# STM32L4R9ZIY6P register map
File version: 1.0
Registers are 32-bit, access not given, reset 0x0 unless marked. A register's access mark holds for its fields unless they carry their own. Offsets are from the block's base; [hi:lo] are bit positions; {n}, {i} and the like mark numbered series; 'fields as' and 'values as' point back to an identical list.

## ADC1
Base 0x50040000
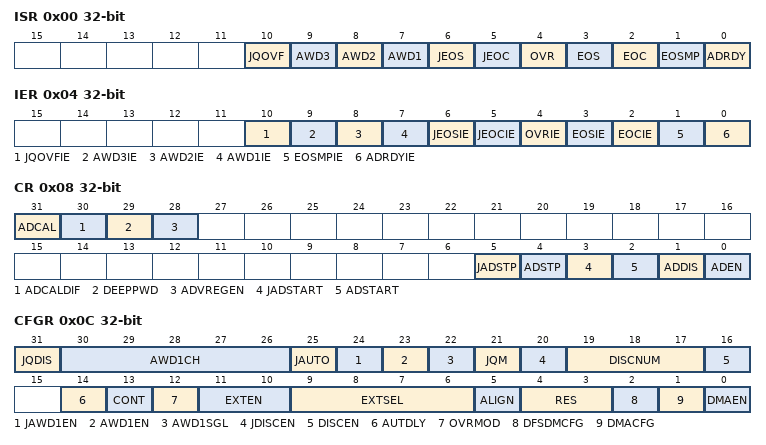
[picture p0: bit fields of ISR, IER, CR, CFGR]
0x00 ISR
  [10] JQOVF, [9] AWD3, [8] AWD2, [7] AWD1, [6] JEOS, [5] JEOC, [4] OVR, [3] EOS, [2] EOC, [1] EOSMP, [0] ADRDY
0x04 IER
  [10] JQOVFIE, [9] AWD3IE, [8] AWD2IE, [7] AWD1IE, [6] JEOSIE, [5] JEOCIE, [4] OVRIE, [3] EOSIE, [2] EOCIE, [1] EOSMPIE, [0] ADRDYIE
0x08 CR
  [31] ADCAL, [30] ADCALDIF, [29] DEEPPWD, [28] ADVREGEN, [5] JADSTP, [4] ADSTP, [3] JADSTART, [2] ADSTART, [1] ADDIS, [0] ADEN
0x0C CFGR
  [31] JQDIS, [30:26] AWD1CH, [25] JAUTO, [24] JAWD1EN, [23] AWD1EN, [22] AWD1SGL, [21] JQM, [20] JDISCEN, [19:17] DISCNUM, [16] DISCEN, [14] AUTDLY, [13] CONT, [12] OVRMOD, [11:10] EXTEN, [9:6] EXTSEL, [5] ALIGN, [4:3] RES, [2] DFSDMCFG, [1] DMACFG, [0] DMAEN
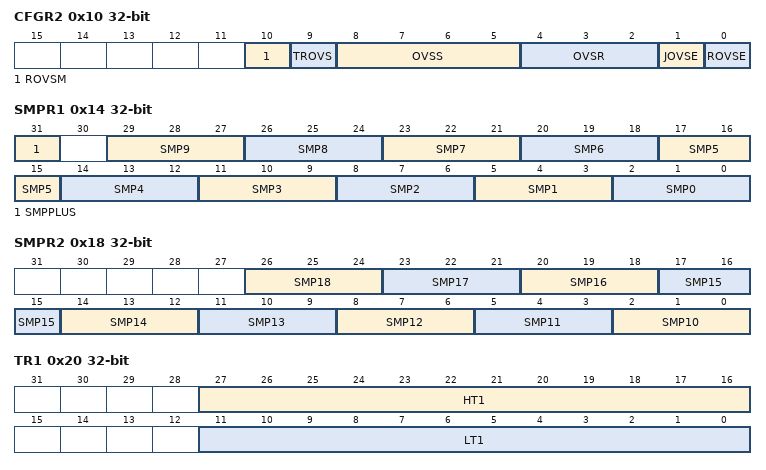
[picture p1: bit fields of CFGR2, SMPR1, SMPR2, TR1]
0x10 CFGR2
  [10] ROVSM, [9] TROVS, [8:5] OVSS, [4:2] OVSR, [1] JOVSE, [0] ROVSE
0x14 SMPR1
  [31] SMPPLUS, [3n+2:3n] SMP{n} (n=0..9)
0x18 SMPR2
  [3n-28:3n-30] SMP{n} (n=10..18)
0x20 TR1
  [27:16] HT1, [11:0] LT1
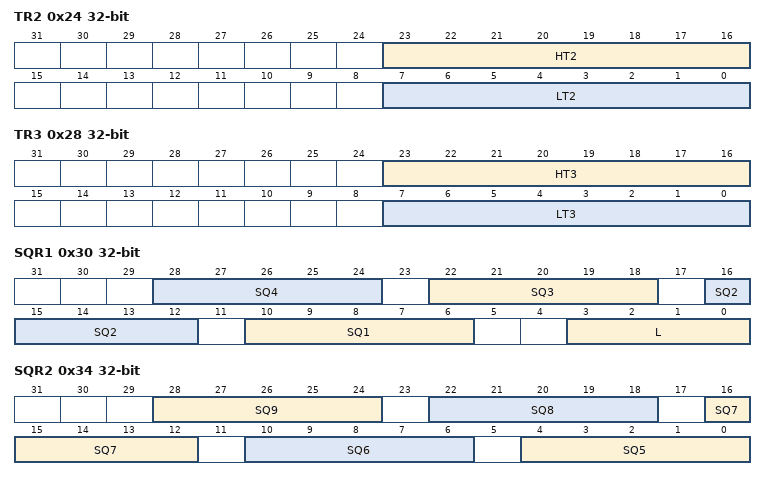
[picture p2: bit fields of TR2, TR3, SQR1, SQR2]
0x24 TR2
  [23:16] HT2, [7:0] LT2
0x28 TR3
  [23:16] HT3, [7:0] LT3
0x30 SQR1
  [6n+4:6n] SQ{n} (n=1..4), [3:0] L
0x34 SQR2
  [6n-26:6n-30] SQ{n} (n=5..9)
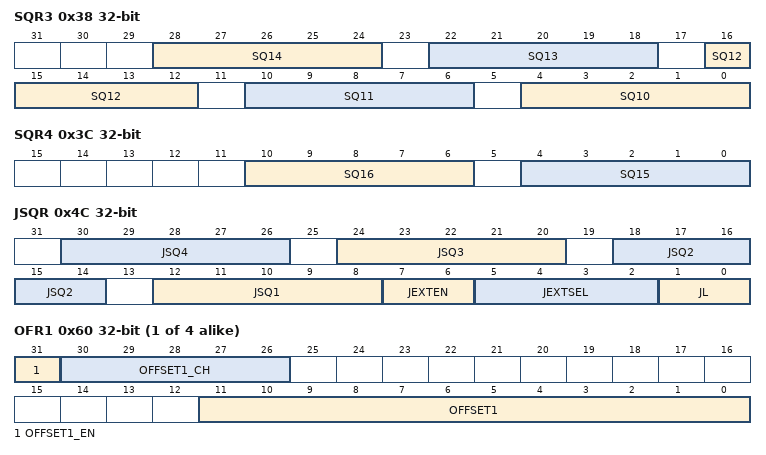
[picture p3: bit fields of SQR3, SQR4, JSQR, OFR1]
0x38 SQR3
  [6n-56:6n-60] SQ{n} (n=10..14)
0x3C SQR4
  [10:6] SQ16, [4:0] SQ15
0x40 DR
  [15:0] RDATA
0x4C JSQR
  [6n+6:6n+2] JSQ{n} (n=1..4), [7:6] JEXTEN, [5:2] JEXTSEL, [1:0] JL
{0x5C+4i} OFR{i} (i=1..4)
  [31] OFFSET{i}_EN, [30:26] OFFSET{i}_CH, [11:0] OFFSET{i}
{0x7C+4i} JDR{i} (i=1..4)
  [15:0] JDATA
0xA0 AWD2CR
  [18:0] AWD2CH
0xA4 AWD3CR
  [18:0] AWD3CH
0xB0 DIFSEL
  [18:0] DIFSEL
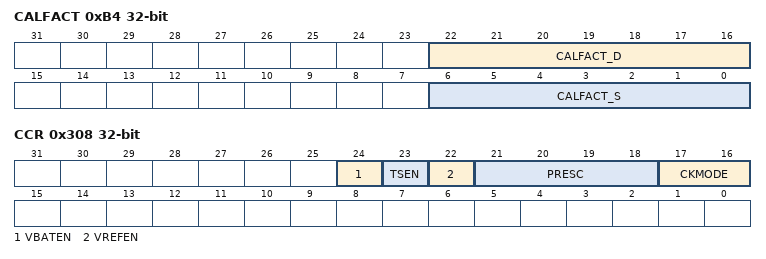
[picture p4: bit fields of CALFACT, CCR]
0xB4 CALFACT
  [22:16] CALFACT_D, [6:0] CALFACT_S
0x308 CCR
  [24] VBATEN, [23] TSEN, [22] VREFEN, [21:18] PRESC, [17:16] CKMODE

## DCMI
Base 0x50050000
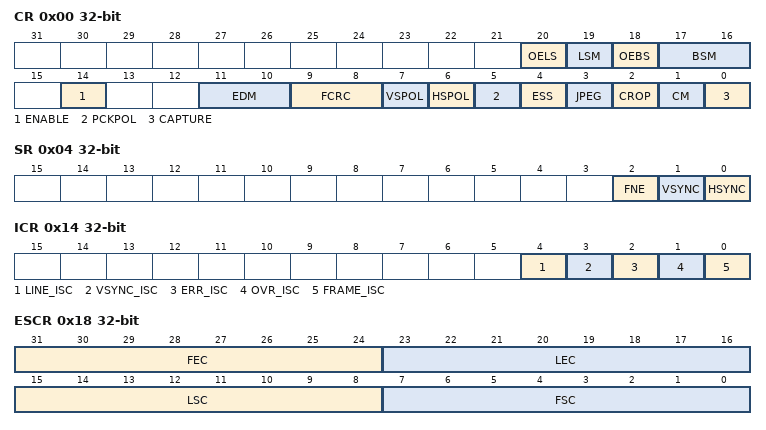
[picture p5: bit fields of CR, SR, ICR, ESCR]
0x00 CR
  [20] OELS, [19] LSM, [18] OEBS, [17:16] BSM, [14] ENABLE, [11:10] EDM, [9:8] FCRC, [7] VSPOL, [6] HSPOL, [5] PCKPOL, [4] ESS, [3] JPEG, [2] CROP, [1] CM, [0] CAPTURE
0x04 SR
  [2] FNE, [1] VSYNC, [0] HSYNC
0x08 RISR
0x0C IER
  [4] LINE_IE, [3] VSYNC_IE, [2] ERR_IE, [1] OVR_IE, [4:0] INT_IE
0x10 MISR
0x14 ICR
  [4] LINE_ISC, [3] VSYNC_ISC, [2] ERR_ISC, [1] OVR_ISC, [0] FRAME_ISC
0x18 ESCR
  [31:24] FEC, [23:16] LEC, [15:8] LSC, [7:0] FSC
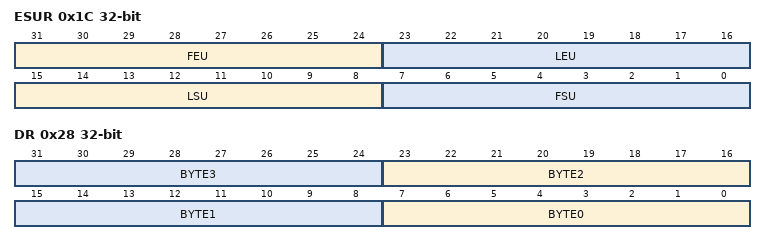
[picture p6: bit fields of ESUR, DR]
0x1C ESUR
  [31:24] FEU, [23:16] LEU, [15:8] LSU, [7:0] FSU
0x20 CWSTRTR
0x24 CWSIZER
0x28 DR
  [8n+7:8n] BYTE{n} (n=0..3)

## RNG
Base 0x50060800
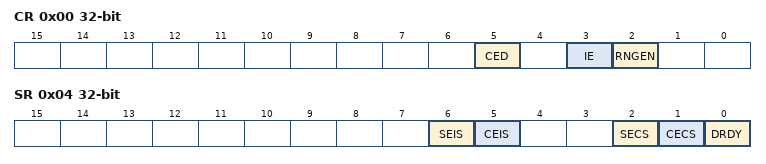
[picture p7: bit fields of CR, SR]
0x00 CR
  [5] CED, [3] IE, [2] RNGEN
0x04 SR
  [6] SEIS, [5] CEIS, [2] SECS, [1] CECS, [0] DRDY
0x08 DR

## OCTOSPIM
Base 0x50061C00
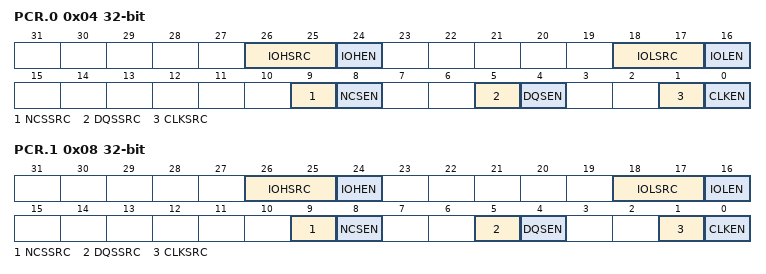
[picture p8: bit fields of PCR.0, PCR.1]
0x04 PCR.0
  [26:25] IOHSRC, [24] IOHEN, [18:17] IOLSRC, [16] IOLEN, [9] NCSSRC, [8] NCSEN, [5] DQSSRC, [4] DQSEN, [1] CLKSRC, [0] CLKEN
0x08 PCR.1
  fields as PCR.0

## SDMMC1
Base 0x50062400
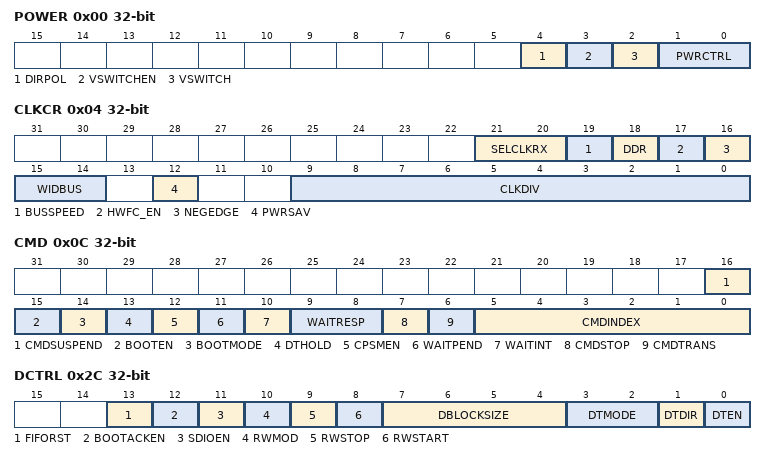
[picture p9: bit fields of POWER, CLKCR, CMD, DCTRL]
0x00 POWER
  [4] DIRPOL, [3] VSWITCHEN, [2] VSWITCH, [1:0] PWRCTRL
0x04 CLKCR
  [21:20] SELCLKRX, [19] BUSSPEED, [18] DDR, [17] HWFC_EN, [16] NEGEDGE, [15:14] WIDBUS, [12] PWRSAV, [9:0] CLKDIV
0x08 ARG
  [31:0] CMDARG
0x0C CMD
  [16] CMDSUSPEND, [15] BOOTEN, [14] BOOTMODE, [13] DTHOLD, [12] CPSMEN, [11] WAITPEND, [10] WAITINT, [9:8] WAITRESP, [7] CMDSTOP, [6] CMDTRANS, [5:0] CMDINDEX
0x10 RESPCMD
  [5:0] RESPCMD
{0x10+4i} RESP{i} (i=1..4)
  [31:0] CARDSTATUS{i}
0x24 DTIMER
  [31:0] DATATIME
0x28 DLEN
  [24:0] DATALENGTH
0x2C DCTRL
  [13] FIFORST, [12] BOOTACKEN, [11] SDIOEN, [10] RWMOD, [9] RWSTOP, [8] RWSTART, [7:4] DBLOCKSIZE, [3:2] DTMODE, [1] DTDIR, [0] DTEN
0x30 DCOUNT
  [24:0] DATACOUNT
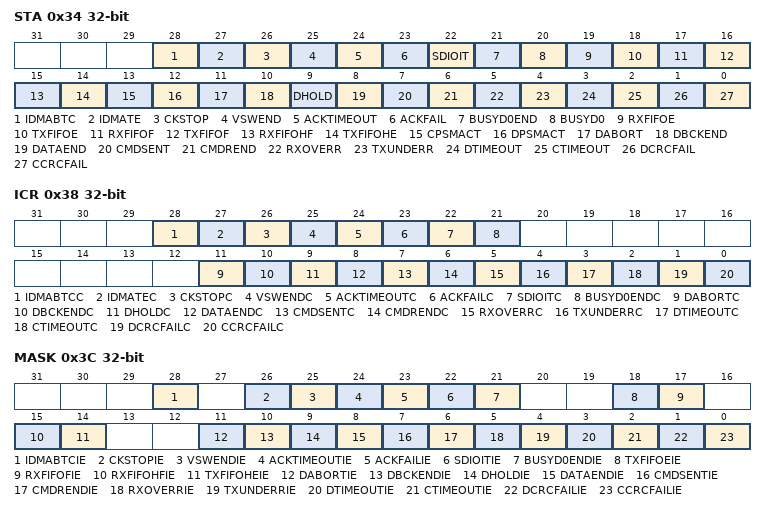
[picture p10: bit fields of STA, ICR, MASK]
0x34 STA
  [28] IDMABTC, [27] IDMATE, [26] CKSTOP, [25] VSWEND, [24] ACKTIMEOUT, [23] ACKFAIL, [22] SDIOIT, [21] BUSYD0END, [20] BUSYD0, [19] RXFIFOE, [18] TXFIFOE, [17] RXFIFOF, [16] TXFIFOF, [15] RXFIFOHF, [14] TXFIFOHE, [13] CPSMACT, [12] DPSMACT, [11] DABORT, [10] DBCKEND, [9] DHOLD, [8] DATAEND, [7] CMDSENT, [6] CMDREND, [5] RXOVERR, [4] TXUNDERR, [3] DTIMEOUT, [2] CTIMEOUT, [1] DCRCFAIL, [0] CCRCFAIL
0x38 ICR
  [28] IDMABTCC, [27] IDMATEC, [26] CKSTOPC, [25] VSWENDC, [24] ACKTIMEOUTC, [23] ACKFAILC, [22] SDIOITC, [21] BUSYD0ENDC, [11] DABORTC, [10] DBCKENDC, [9] DHOLDC, [8] DATAENDC, [7] CMDSENTC, [6] CMDRENDC, [5] RXOVERRC, [4] TXUNDERRC, [3] DTIMEOUTC, [2] CTIMEOUTC, [1] DCRCFAILC, [0] CCRCFAILC
0x3C MASK
  [28] IDMABTCIE, [26] CKSTOPIE, [25] VSWENDIE, [24] ACKTIMEOUTIE, [23] ACKFAILIE, [22] SDIOITIE, [21] BUSYD0ENDIE, [18] TXFIFOEIE, [17] RXFIFOFIE, [15] RXFIFOHFIE, [14] TXFIFOHEIE, [11] DABORTIE, [10] DBCKENDIE, [9] DHOLDIE, [8] DATAENDIE, [7] CMDSENTIE, [6] CMDRENDIE, [5] RXOVERRIE, [4] TXUNDERRIE, [3] DTIMEOUTIE, [2] CTIMEOUTIE, [1] DCRCFAILIE, [0] CCRCFAILIE
0x40 ACKTIME
0x50 IDMACTRL
0x54 IDMABSIZE
0x58 IDMABASE0
0x5C IDMABASE1
0x80 FIFO
  [31:0] FIFODATA

## FMC_Bank1_R
Base 0xA0000000
0x00 BTCR.0
0x04 BTCR.1
0x08 BTCR.2
0x0C BTCR.3
0x10 BTCR.4
0x14 BTCR.5
0x18 BTCR.6
0x1C BTCR.7

## FMC_Bank3_R
Base 0xA0000080
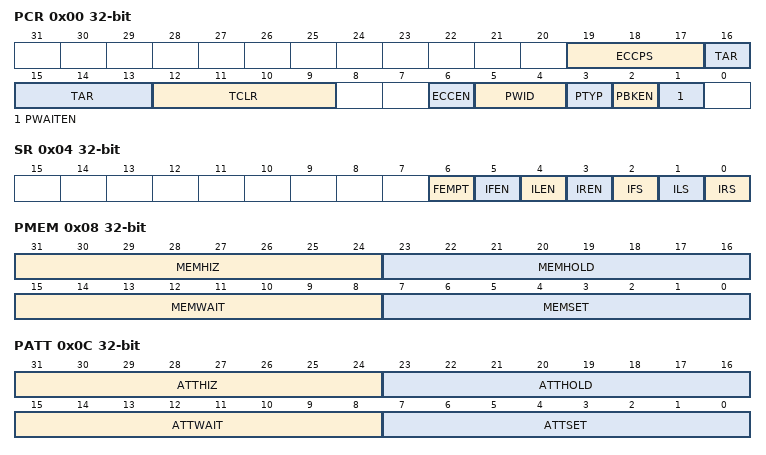
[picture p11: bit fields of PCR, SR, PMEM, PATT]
0x00 PCR
  [19:17] ECCPS, [16:13] TAR, [12:9] TCLR, [6] ECCEN, [5:4] PWID, [3] PTYP, [2] PBKEN, [1] PWAITEN
0x04 SR
  [6] FEMPT, [5] IFEN, [4] ILEN, [3] IREN, [2] IFS, [1] ILS, [0] IRS
0x08 PMEM
  [31:24] MEMHIZ, [23:16] MEMHOLD, [15:8] MEMWAIT, [7:0] MEMSET
0x0C PATT
  [31:24] ATTHIZ, [23:16] ATTHOLD, [15:8] ATTWAIT, [7:0] ATTSET
0x14 ECCR
  [31:0] ECC

## FMC_Bank1E_R
Base 0xA0000104
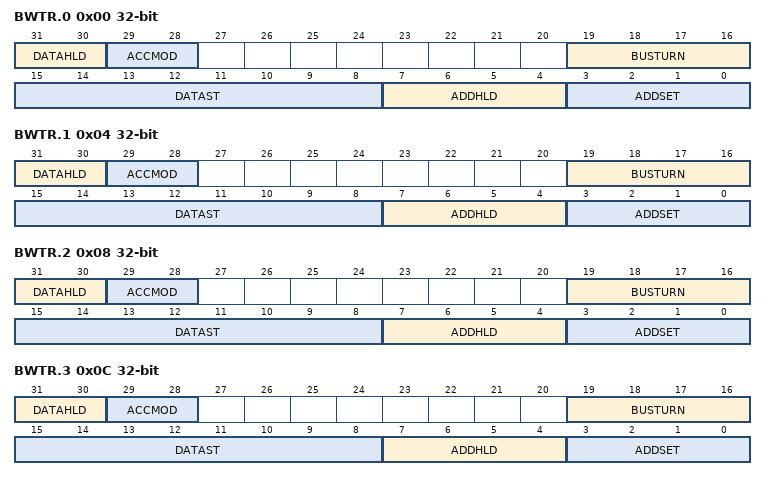
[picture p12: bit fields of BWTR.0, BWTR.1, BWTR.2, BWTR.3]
0x00 BWTR.0
  [31:30] DATAHLD, [29:28] ACCMOD, [19:16] BUSTURN, [15:8] DATAST, [7:4] ADDHLD, [3:0] ADDSET
0x04 BWTR.1
  fields as BWTR.0
0x08 BWTR.2
  fields as BWTR.0
0x0C BWTR.3
  fields as BWTR.0
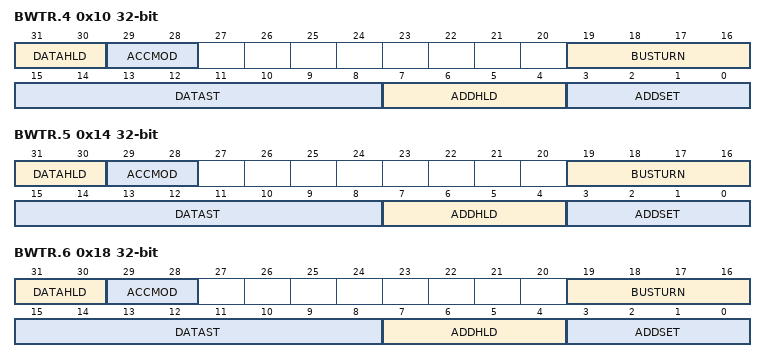
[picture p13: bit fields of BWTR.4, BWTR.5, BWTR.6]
0x10 BWTR.4
  fields as BWTR.0
0x14 BWTR.5
  fields as BWTR.0
0x18 BWTR.6
  fields as BWTR.0

## OCTOSPI1
Base 0xA0001000
Same registers: OCTOSPI2 0xA0001400
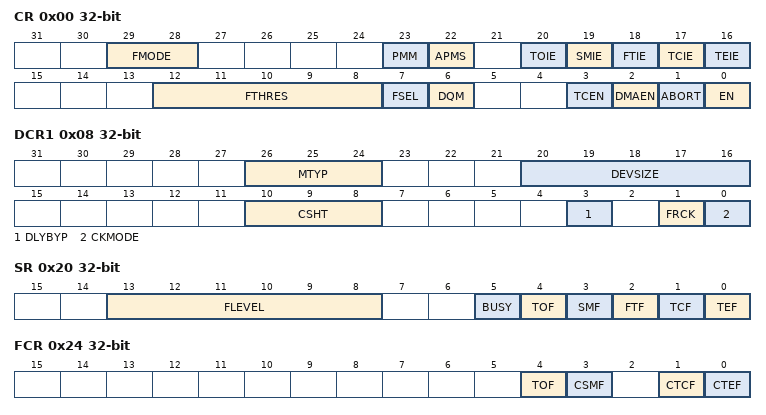
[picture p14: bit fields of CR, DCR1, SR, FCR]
0x00 CR
  [29:28] FMODE, [23] PMM, [22] APMS, [20] TOIE, [19] SMIE, [18] FTIE, [17] TCIE, [16] TEIE, [12:8] FTHRES, [7] FSEL, [6] DQM, [3] TCEN, [2] DMAEN, [1] ABORT, [0] EN
0x08 DCR1
  [26:24] MTYP, [20:16] DEVSIZE, [10:8] CSHT, [3] DLYBYP, [1] FRCK, [0] CKMODE
0x0C DCR2
  [7:0] PRESCALER
0x10 DCR3
  [20:16] CSBOUND
0x20 SR
  [13:8] FLEVEL, [5] BUSY, [4] TOF, [3] SMF, [2] FTF, [1] TCF, [0] TEF
0x24 FCR
  [4] TOF, [3] CSMF, [1] CTCF, [0] CTEF
0x40 DLR
  [31:0] DL
0x48 AR
  [31:0] ADDRESS
0x50 DR
  [31:0] DATA
0x80 PSMKR
  [31:0] MASK
0x88 PSMAR
  [31:0] MATCH
0x90 PIR
  [15:0] INTERVAL
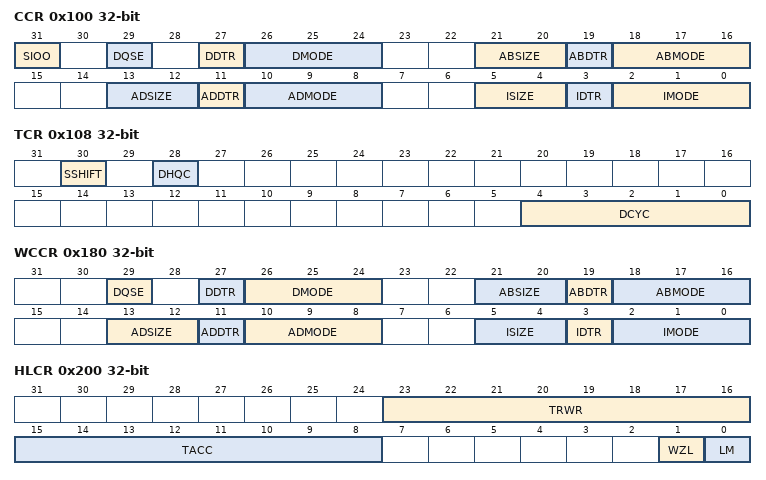
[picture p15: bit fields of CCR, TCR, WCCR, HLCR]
0x100 CCR
  [31] SIOO, [29] DQSE, [27] DDTR, [26:24] DMODE, [21:20] ABSIZE, [19] ABDTR, [18:16] ABMODE, [13:12] ADSIZE, [11] ADDTR, [10:8] ADMODE, [5:4] ISIZE, [3] IDTR, [2:0] IMODE
0x108 TCR
  [30] SSHIFT, [28] DHQC, [4:0] DCYC
0x110 IR
  [31:0] INSTRUCTION
0x120 ABR
  [31:0] ALTERNATE
0x130 LPTR
  [15:0] TIMEOUT
0x180 WCCR
  [29] DQSE, [27] DDTR, [26:24] DMODE, [21:20] ABSIZE, [19] ABDTR, [18:16] ABMODE, [13:12] ADSIZE, [11] ADDTR, [10:8] ADMODE, [5:4] ISIZE, [3] IDTR, [2:0] IMODE
0x188 WTCR
  [4:0] DCYC
0x190 WIR
  [31:0] INSTRUCTION
0x1A0 WABR
  [31:0] ALTERNATE
0x200 HLCR
  [23:16] TRWR, [15:8] TACC, [1] WZL, [0] LM

## DBGMCU
Base 0xE0042000
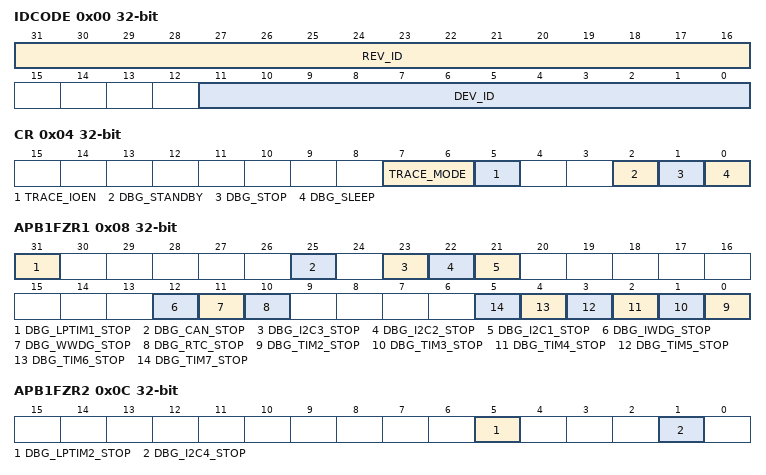
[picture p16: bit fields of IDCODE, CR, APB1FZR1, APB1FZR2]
0x00 IDCODE
  [31:16] REV_ID, [11:0] DEV_ID
0x04 CR
  [7:6] TRACE_MODE, [5] TRACE_IOEN, [2] DBG_STANDBY, [1] DBG_STOP, [0] DBG_SLEEP
0x08 APB1FZR1
  [31] DBG_LPTIM1_STOP, [25] DBG_CAN_STOP, [23] DBG_I2C3_STOP, [22] DBG_I2C2_STOP, [21] DBG_I2C1_STOP, [12] DBG_IWDG_STOP, [11] DBG_WWDG_STOP, [10] DBG_RTC_STOP, [n-2] DBG_TIM{n}_STOP (n=2..7)
0x0C APB1FZR2
  [5] DBG_LPTIM2_STOP, [1] DBG_I2C4_STOP
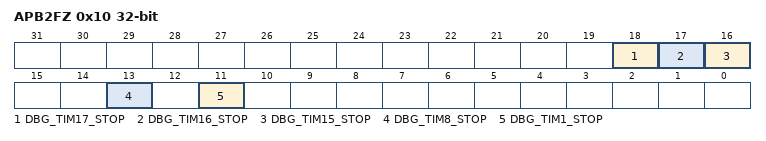
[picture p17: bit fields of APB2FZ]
0x10 APB2FZ
  [18] DBG_TIM17_STOP, [17] DBG_TIM16_STOP, [16] DBG_TIM15_STOP, [13] DBG_TIM8_STOP, [11] DBG_TIM1_STOP
